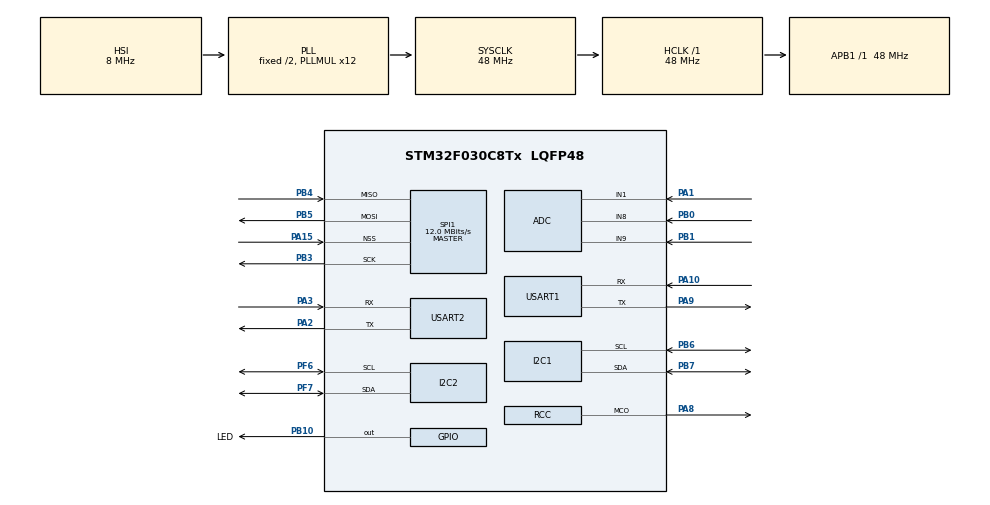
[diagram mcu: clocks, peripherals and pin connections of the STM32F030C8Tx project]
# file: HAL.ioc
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I2C2.Timing=0x20303E5D
Mcu.Family=STM32F0
Mcu.Name=STM32F030C8Tx
Mcu.Package=LQFP48
PA1.Mode=IN1
PA1.Signal=ADC_IN1
PA10.Mode=Asynchronous
PA10.Signal=USART1_RX
PA13.Mode=Serial_Wire
PA13.Signal=SYS_SWDIO
PA14.Mode=Serial_Wire
PA14.Signal=SYS_SWCLK
PA15.Mode=NSS_Signal_Hard_Input
PA15.Signal=SPI1_NSS
PA2.Mode=Asynchronous
PA2.Signal=USART2_TX
PA3.Mode=Asynchronous
PA3.Signal=USART2_RX
PA8.Mode=Clock-out
PA8.Signal=RCC_MCO
PA9.Mode=Asynchronous
PA9.Signal=USART1_TX
PB0.Mode=IN8
PB0.Signal=ADC_IN8
PB1.Mode=IN9
PB1.Signal=ADC_IN9
PB10.GPIO_Label=LED
PB10.Signal=GPIO_Output
PB3.Mode=Full_Duplex_Master
PB3.Signal=SPI1_SCK
PB4.Mode=Full_Duplex_Master
PB4.Signal=SPI1_MISO
PB5.Mode=Full_Duplex_Master
PB5.Signal=SPI1_MOSI
PB6.Mode=I2C
PB6.Signal=I2C1_SCL
PB7.Mode=I2C
PB7.Signal=I2C1_SDA
PF0-OSC_IN.Mode=HSE-External-Oscillator
PF0-OSC_IN.Signal=RCC_OSC_IN
PF1-OSC_OUT.Mode=HSE-External-Oscillator
PF1-OSC_OUT.Signal=RCC_OSC_OUT
PF6.Mode=I2C
PF6.Signal=I2C2_SCL
PF7.Mode=I2C
PF7.Signal=I2C2_SDA
ProjectManager.HeapSize=0x200
ProjectManager.StackSize=0x400
ProjectManager.TargetToolchain=TrueSTUDIO
RCC.AHBFreq_Value=48000000
RCC.APB1Freq_Value=48000000
RCC.APB1TimFreq_Value=48000000
RCC.HCLKFreq_Value=48000000
RCC.PLLMUL=RCC_PLL_MUL12
RCC.RCC_MCOSource=RCC_MCO1SOURCE_PLLCLK_DIV2
RCC.SYSCLKFreq_VALUE=48000000
RCC.SYSCLKSource=RCC_SYSCLKSOURCE_PLLCLK
SPI1.BaudRatePrescaler=SPI_BAUDRATEPRESCALER_4
SPI1.CalculateBaudRate=12.0 MBits/s
SPI1.Direction=SPI_DIRECTION_2LINES
SPI1.Mode=SPI_MODE_MASTER
SPI1.VirtualNSS=VM_NSSHARD
SPI1.VirtualType=VM_MASTER
USART1.VirtualMode-Asynchronous=VM_ASYNC
USART2.VirtualMode-Asynchronous=VM_ASYNC
board=custom

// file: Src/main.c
/* USER CODE BEGIN Header */
/**
  ******************************************************************************
  * @file           : main.c
  * @brief          : Main program body
  ******************************************************************************
  * @attention
  *
  * <h2><center>&copy; Copyright (c) 2019 STMicroelectronics.
  * All rights reserved.</center></h2>
  *
  * This software component is licensed by ST under BSD 3-Clause license,
  * the "License"; You may not use this file except in compliance with the
  * License. You may obtain a copy of the License at:
  *                        opensource.org/licenses/BSD-3-Clause
  *
  ******************************************************************************
  */
/* USER CODE END Header */

#include "main.h"

ADC_HandleTypeDef hadc;

I2C_HandleTypeDef hi2c1;
I2C_HandleTypeDef hi2c2;

SPI_HandleTypeDef hspi1;

UART_HandleTypeDef huart1;
UART_HandleTypeDef huart2;

void SystemClock_Config(void);
static void MX_GPIO_Init(void);
static void MX_ADC_Init(void);
static void MX_I2C1_Init(void);
static void MX_I2C2_Init(void);
static void MX_SPI1_Init(void);
static void MX_USART1_UART_Init(void);
static void MX_USART2_UART_Init(void);

int main(void)
{

  /* MCU Configuration--------------------------------------------------------*/

  /* Reset of all peripherals, Initializes the Flash interface and the Systick. */
  HAL_Init();

  /* Configure the system clock */
  SystemClock_Config();

  /* Initialize all configured peripherals */
  MX_GPIO_Init();
  MX_ADC_Init();
  MX_I2C1_Init();
  MX_I2C2_Init();
  MX_SPI1_Init();
  MX_USART1_UART_Init();
  MX_USART2_UART_Init();

  /* Infinite loop */
  while (1)
  {

    /* USER CODE BEGIN 3 */
	HAL_GPIO_TogglePin(LED_GPIO_Port, LED_Pin);
	/* Insert delay 1000 ms */
	HAL_Delay(1000);
  }
  /* USER CODE END 3 */
}

void SystemClock_Config(void)
{
  RCC_OscInitTypeDef RCC_OscInitStruct = {0};
  RCC_ClkInitTypeDef RCC_ClkInitStruct = {0};
  RCC_PeriphCLKInitTypeDef PeriphClkInit = {0};

  /** Initializes the CPU, AHB and APB busses clocks
  */
  RCC_OscInitStruct.OscillatorType = RCC_OSCILLATORTYPE_HSI|RCC_OSCILLATORTYPE_HSI14;
  RCC_OscInitStruct.HSIState = RCC_HSI_ON;
  RCC_OscInitStruct.HSI14State = RCC_HSI14_ON;
  RCC_OscInitStruct.HSICalibrationValue = RCC_HSICALIBRATION_DEFAULT;
  RCC_OscInitStruct.HSI14CalibrationValue = 16;
  RCC_OscInitStruct.PLL.PLLState = RCC_PLL_ON;
  RCC_OscInitStruct.PLL.PLLSource = RCC_PLLSOURCE_HSI;
  RCC_OscInitStruct.PLL.PLLMUL = RCC_PLL_MUL12;
  RCC_OscInitStruct.PLL.PREDIV = RCC_PREDIV_DIV1;
  if (HAL_RCC_OscConfig(&RCC_OscInitStruct) != HAL_OK)
  {
    Error_Handler();
  }
  /** Initializes the CPU, AHB and APB busses clocks
  */
  RCC_ClkInitStruct.ClockType = RCC_CLOCKTYPE_HCLK|RCC_CLOCKTYPE_SYSCLK
                              |RCC_CLOCKTYPE_PCLK1;
  RCC_ClkInitStruct.SYSCLKSource = RCC_SYSCLKSOURCE_PLLCLK;
  RCC_ClkInitStruct.AHBCLKDivider = RCC_SYSCLK_DIV1;
  RCC_ClkInitStruct.APB1CLKDivider = RCC_HCLK_DIV1;

  if (HAL_RCC_ClockConfig(&RCC_ClkInitStruct, FLASH_LATENCY_1) != HAL_OK)
  {
    Error_Handler();
  }
  PeriphClkInit.PeriphClockSelection = RCC_PERIPHCLK_USART1|RCC_PERIPHCLK_I2C1;
  PeriphClkInit.Usart1ClockSelection = RCC_USART1CLKSOURCE_PCLK1;
  PeriphClkInit.I2c1ClockSelection = RCC_I2C1CLKSOURCE_HSI;
  if (HAL_RCCEx_PeriphCLKConfig(&PeriphClkInit) != HAL_OK)
  {
    Error_Handler();
  }
  HAL_RCC_MCOConfig(RCC_MCO, RCC_MCO1SOURCE_PLLCLK_DIV2, RCC_MCODIV_1);
}

static void MX_ADC_Init(void)
{

  ADC_ChannelConfTypeDef sConfig = {0};

  /** Configure the global features of the ADC (Clock, Resolution, Data Alignment and number of conversion)
  */
  hadc.Instance = ADC1;
  hadc.Init.ClockPrescaler = ADC_CLOCK_ASYNC_DIV1;
  hadc.Init.Resolution = ADC_RESOLUTION_12B;
  hadc.Init.DataAlign = ADC_DATAALIGN_RIGHT;
  hadc.Init.ScanConvMode = ADC_SCAN_DIRECTION_FORWARD;
  hadc.Init.EOCSelection = ADC_EOC_SINGLE_CONV;
  hadc.Init.LowPowerAutoWait = DISABLE;
  hadc.Init.LowPowerAutoPowerOff = DISABLE;
  hadc.Init.ContinuousConvMode = DISABLE;
  hadc.Init.DiscontinuousConvMode = DISABLE;
  hadc.Init.ExternalTrigConv = ADC_SOFTWARE_START;
  hadc.Init.ExternalTrigConvEdge = ADC_EXTERNALTRIGCONVEDGE_NONE;
  hadc.Init.DMAContinuousRequests = DISABLE;
  hadc.Init.Overrun = ADC_OVR_DATA_PRESERVED;
  if (HAL_ADC_Init(&hadc) != HAL_OK)
  {
    Error_Handler();
  }
  /** Configure for the selected ADC regular channel to be converted.
  */
  sConfig.Channel = ADC_CHANNEL_1;
  sConfig.Rank = ADC_RANK_CHANNEL_NUMBER;
  sConfig.SamplingTime = ADC_SAMPLETIME_1CYCLE_5;
  if (HAL_ADC_ConfigChannel(&hadc, &sConfig) != HAL_OK)
  {
    Error_Handler();
  }
  /** Configure for the selected ADC regular channel to be converted.
  */
  sConfig.Channel = ADC_CHANNEL_8;
  if (HAL_ADC_ConfigChannel(&hadc, &sConfig) != HAL_OK)
  {
    Error_Handler();
  }
  /** Configure for the selected ADC regular channel to be converted.
  */
  sConfig.Channel = ADC_CHANNEL_9;
  if (HAL_ADC_ConfigChannel(&hadc, &sConfig) != HAL_OK)
  {
    Error_Handler();
  }

}

static void MX_I2C1_Init(void)
{

  hi2c1.Instance = I2C1;
  hi2c1.Init.Timing = 0x2000090E;
  hi2c1.Init.OwnAddress1 = 0;
  hi2c1.Init.AddressingMode = I2C_ADDRESSINGMODE_7BIT;
  hi2c1.Init.DualAddressMode = I2C_DUALADDRESS_DISABLE;
  hi2c1.Init.OwnAddress2 = 0;
  hi2c1.Init.OwnAddress2Masks = I2C_OA2_NOMASK;
  hi2c1.Init.GeneralCallMode = I2C_GENERALCALL_DISABLE;
  hi2c1.Init.NoStretchMode = I2C_NOSTRETCH_DISABLE;
  if (HAL_I2C_Init(&hi2c1) != HAL_OK)
  {
    Error_Handler();
  }
  /** Configure Analogue filter
  */
  if (HAL_I2CEx_ConfigAnalogFilter(&hi2c1, I2C_ANALOGFILTER_ENABLE) != HAL_OK)
  {
    Error_Handler();
  }
  /** Configure Digital filter
  */
  if (HAL_I2CEx_ConfigDigitalFilter(&hi2c1, 0) != HAL_OK)
  {
    Error_Handler();
  }

}

static void MX_I2C2_Init(void)
{

  hi2c2.Instance = I2C2;
  hi2c2.Init.Timing = 0x20303E5D;
  hi2c2.Init.OwnAddress1 = 0;
  hi2c2.Init.AddressingMode = I2C_ADDRESSINGMODE_7BIT;
  hi2c2.Init.DualAddressMode = I2C_DUALADDRESS_DISABLE;
  hi2c2.Init.OwnAddress2 = 0;
  hi2c2.Init.OwnAddress2Masks = I2C_OA2_NOMASK;
  hi2c2.Init.GeneralCallMode = I2C_GENERALCALL_DISABLE;
  hi2c2.Init.NoStretchMode = I2C_NOSTRETCH_DISABLE;
  if (HAL_I2C_Init(&hi2c2) != HAL_OK)
  {
    Error_Handler();
  }
  /** Configure Analogue filter
  */
  if (HAL_I2CEx_ConfigAnalogFilter(&hi2c2, I2C_ANALOGFILTER_ENABLE) != HAL_OK)
  {
    Error_Handler();
  }
  /** Configure Digital filter
  */
  if (HAL_I2CEx_ConfigDigitalFilter(&hi2c2, 0) != HAL_OK)
  {
    Error_Handler();
  }

}

static void MX_SPI1_Init(void)
{

  /* SPI1 parameter configuration*/
  hspi1.Instance = SPI1;
  hspi1.Init.Mode = SPI_MODE_MASTER;
  hspi1.Init.Direction = SPI_DIRECTION_2LINES;
  hspi1.Init.DataSize = SPI_DATASIZE_4BIT;
  hspi1.Init.CLKPolarity = SPI_POLARITY_LOW;
  hspi1.Init.CLKPhase = SPI_PHASE_1EDGE;
  hspi1.Init.NSS = SPI_NSS_HARD_INPUT;
  hspi1.Init.BaudRatePrescaler = SPI_BAUDRATEPRESCALER_4;
  hspi1.Init.FirstBit = SPI_FIRSTBIT_MSB;
  hspi1.Init.TIMode = SPI_TIMODE_DISABLE;
  hspi1.Init.CRCCalculation = SPI_CRCCALCULATION_DISABLE;
  hspi1.Init.CRCPolynomial = 7;
  hspi1.Init.CRCLength = SPI_CRC_LENGTH_DATASIZE;
  hspi1.Init.NSSPMode = SPI_NSS_PULSE_ENABLE;
  if (HAL_SPI_Init(&hspi1) != HAL_OK)
  {
    Error_Handler();
  }

}

static void MX_USART1_UART_Init(void)
{

  huart1.Instance = USART1;
  huart1.Init.BaudRate = 38400;
  huart1.Init.WordLength = UART_WORDLENGTH_8B;
  huart1.Init.StopBits = UART_STOPBITS_1;
  huart1.Init.Parity = UART_PARITY_NONE;
  huart1.Init.Mode = UART_MODE_TX_RX;
  huart1.Init.HwFlowCtl = UART_HWCONTROL_NONE;
  huart1.Init.OverSampling = UART_OVERSAMPLING_16;
  huart1.Init.OneBitSampling = UART_ONE_BIT_SAMPLE_DISABLE;
  huart1.AdvancedInit.AdvFeatureInit = UART_ADVFEATURE_NO_INIT;
  if (HAL_UART_Init(&huart1) != HAL_OK)
  {
    Error_Handler();
  }

}

static void MX_USART2_UART_Init(void)
{

  huart2.Instance = USART2;
  huart2.Init.BaudRate = 38400;
  huart2.Init.WordLength = UART_WORDLENGTH_8B;
  huart2.Init.StopBits = UART_STOPBITS_1;
  huart2.Init.Parity = UART_PARITY_NONE;
  huart2.Init.Mode = UART_MODE_TX_RX;
  huart2.Init.HwFlowCtl = UART_HWCONTROL_NONE;
  huart2.Init.OverSampling = UART_OVERSAMPLING_16;
  huart2.Init.OneBitSampling = UART_ONE_BIT_SAMPLE_DISABLE;
  huart2.AdvancedInit.AdvFeatureInit = UART_ADVFEATURE_NO_INIT;
  if (HAL_UART_Init(&huart2) != HAL_OK)
  {
    Error_Handler();
  }

}

static void MX_GPIO_Init(void)
{
  GPIO_InitTypeDef GPIO_InitStruct = {0};

  /* GPIO Ports Clock Enable */
  __HAL_RCC_GPIOF_CLK_ENABLE();
  __HAL_RCC_GPIOA_CLK_ENABLE();
  __HAL_RCC_GPIOB_CLK_ENABLE();

  /*Configure GPIO pin Output Level */
  HAL_GPIO_WritePin(LED_GPIO_Port, LED_Pin, GPIO_PIN_RESET);

  /*Configure GPIO pin : LED_Pin */
  GPIO_InitStruct.Pin = LED_Pin;
  GPIO_InitStruct.Mode = GPIO_MODE_OUTPUT_PP;
  GPIO_InitStruct.Pull = GPIO_NOPULL;
  GPIO_InitStruct.Speed = GPIO_SPEED_FREQ_LOW;
  HAL_GPIO_Init(LED_GPIO_Port, &GPIO_InitStruct);

  /*Configure GPIO pin : PA8 */
  GPIO_InitStruct.Pin = GPIO_PIN_8;
  GPIO_InitStruct.Mode = GPIO_MODE_AF_PP;
  GPIO_InitStruct.Pull = GPIO_NOPULL;
  GPIO_InitStruct.Speed = GPIO_SPEED_FREQ_LOW;
  GPIO_InitStruct.Alternate = GPIO_AF0_MCO;
  HAL_GPIO_Init(GPIOA, &GPIO_InitStruct);

}

void Error_Handler(void)
{
}

/************************ (C) COPYRIGHT STMicroelectronics *****END OF FILE****/
